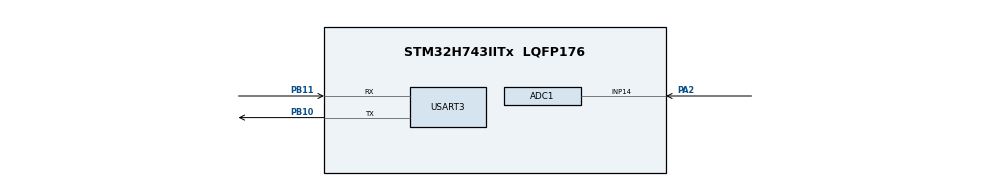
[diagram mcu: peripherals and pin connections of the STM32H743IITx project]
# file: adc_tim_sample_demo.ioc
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ADC1.Channel-0\#ChannelRegularConversion=ADC_CHANNEL_14
ADC1.ConversionDataManagement=ADC_CONVERSIONDATA_DMA_ONESHOT
ADC1.ExternalTrigConv=ADC_EXTERNALTRIG_T3_TRGO
ADC1.NbrOfConversionFlag=1
ADC1.OffsetNumber-0\#ChannelRegularConversion=ADC_OFFSET_NONE
ADC1.OffsetSignedSaturation-0\#ChannelRegularConversion=DISABLE
ADC1.Rank-0\#ChannelRegularConversion=1
ADC1.SamplingTime-0\#ChannelRegularConversion=ADC_SAMPLETIME_1CYCLE_5
ADC1.master=1
CORTEX_M7.default_mode_Activation=1
Dma.ADC1.0.Direction=DMA_PERIPH_TO_MEMORY
Dma.ADC1.0.EventEnable=DISABLE
Dma.ADC1.0.FIFOMode=DMA_FIFOMODE_DISABLE
Dma.ADC1.0.Instance=DMA1_Stream0
Dma.ADC1.0.MemDataAlignment=DMA_MDATAALIGN_HALFWORD
Dma.ADC1.0.MemInc=DMA_MINC_ENABLE
Dma.ADC1.0.Mode=DMA_NORMAL
Dma.ADC1.0.PeriphDataAlignment=DMA_PDATAALIGN_HALFWORD
Dma.ADC1.0.PeriphInc=DMA_PINC_DISABLE
Dma.ADC1.0.Polarity=HAL_DMAMUX_REQ_GEN_RISING
Dma.ADC1.0.Priority=DMA_PRIORITY_LOW
Dma.ADC1.0.RequestNumber=1
Dma.ADC1.0.SignalID=NONE
Dma.ADC1.0.SyncEnable=DISABLE
Dma.ADC1.0.SyncPolarity=HAL_DMAMUX_SYNC_NO_EVENT
Dma.ADC1.0.SyncRequestNumber=1
Dma.ADC1.0.SyncSignalID=NONE
Dma.Request0=ADC1
Mcu.Family=STM32H7
Mcu.Name=STM32H743IITx
Mcu.Package=LQFP176
NVIC.DMA1_Stream0_IRQn=true\:0\:0\:false\:false\:true\:false\:true\:true
NVIC.PriorityGroup=NVIC_PRIORITYGROUP_4
PA13\ (JTMS/SWDIO).Mode=Serial_Wire
PA13\ (JTMS/SWDIO).Signal=DEBUG_JTMS-SWDIO
PA14\ (JTCK/SWCLK).Mode=Serial_Wire
PA14\ (JTCK/SWCLK).Signal=DEBUG_JTCK-SWCLK
PA2.Signal=ADCx_INP14
PB10.Mode=Asynchronous
PB10.Signal=USART3_TX
PB11.Mode=Asynchronous
PB11.Signal=USART3_RX
PH0-OSC_IN\ (PH0).Mode=HSE-External-Clock-Source
PH0-OSC_IN\ (PH0).Signal=RCC_OSC_IN
ProjectManager.HeapSize=0x200
ProjectManager.StackSize=0x400
ProjectManager.TargetToolchain=MDK-ARM V5.32
RCC.ADCFreq_Value=75000000
RCC.APB1Freq_Value=120000000
RCC.APB2Freq_Value=120000000
RCC.APB3Freq_Value=120000000
RCC.APB4Freq_Value=120000000
RCC.CortexFreq_Value=480000000
RCC.D1PPRE=RCC_APB3_DIV2
RCC.D2PPRE1=RCC_APB1_DIV2
RCC.D2PPRE2=RCC_APB2_DIV2
RCC.D3PPRE=RCC_APB4_DIV2
RCC.DIVM1=5
RCC.DIVM2=2
RCC.DIVN1=192
RCC.DIVN2=12
RCC.HCLKFreq_Value=240000000
RCC.HPRE=RCC_HCLK_DIV2
RCC.PLL2FRACN=0
RCC.PLL3FRACN=0
RCC.PLLFRACN=0
RCC.PLLSourceVirtual=RCC_PLLSOURCE_HSE
RCC.SYSCLKFreq_VALUE=480000000
RCC.SYSCLKSource=RCC_SYSCLKSOURCE_PLLCLK
RCC.USBFreq_Value=480000000
SH.ADCx_INP14.0=ADC1_INP14,IN14-Single-Ended
TIM3.AutoReloadPreload=TIM_AUTORELOAD_PRELOAD_ENABLE
TIM3.Period=199
TIM3.Prescaler=23
TIM3.TIM_MasterOutputTrigger=TIM_TRGO_UPDATE
USART3.VirtualMode-Asynchronous=VM_ASYNC
VP_MEMORYMAP_VS_MEMORYMAP.Mode=CurAppReg
VP_TIM3_VS_ClockSourceINT.Mode=Internal
board=custom

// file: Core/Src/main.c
/* USER CODE BEGIN Header */
/**
  ******************************************************************************
  * @file           : main.c
  * @brief          : Main program body
  ******************************************************************************
  * @attention
  *
  * Copyright (c) 2026 STMicroelectronics.
  * All rights reserved.
  *
  * This software is licensed under terms that can be found in the LICENSE file
  * in the root directory of this software component.
  * If no LICENSE file comes with this software, it is provided AS-IS.
  *
  ******************************************************************************
  */
/* USER CODE END Header */
#include "main.h"
#include "adc.h"
#include "dma.h"
#include "tim.h"
#include "usart.h"
#include "gpio.h"

/* USER CODE BEGIN Includes */
#include "AdcProc.h"
#include "tjc_usart_hmi.h"
#include <stdlib.h>
#include <stdio.h>
/* USER CODE END Includes */

/* USER CODE BEGIN PD */
#define sampleLEN 2048
#define showPoints 128  // 设定发送点数，通过平均降采样实现平滑
/* USER CODE END PD */

/* USER CODE BEGIN PV */
__IO uint8_t AdcConvEnd = 0;
uint16_t ADCBuffer[sampleLEN];
/* USER CODE END PV */

void SystemClock_Config(void);
static void MPU_Config(void);
/* USER CODE BEGIN PFP */
void toShow(uint16_t* ADCBuffer, uint16_t LEN);
/* USER CODE END PFP */

int main(void)
{

  /* MPU Configuration--------------------------------------------------------*/
  MPU_Config();

  /* MCU Configuration--------------------------------------------------------*/

  /* Reset of all peripherals, Initializes the Flash interface and the Systick. */
  HAL_Init();

  /* Configure the system clock */
  SystemClock_Config();

  /* Initialize all configured peripherals */
  MX_GPIO_Init();
  MX_DMA_Init();
  MX_ADC1_Init();
  MX_TIM3_Init();
  MX_USART3_UART_Init();

  /* Infinite loop */
  while (1)
  {

    /* USER CODE BEGIN 3 */
    AdcConvEnd = 0;//刷新DMA结束标志位

	  HAL_TIM_Base_Start(&htim3);     //开启定时器3

	  //开启ADC采集，结束后触发终端回调函数HAL_ADC_ConvCpltCallback
	  HAL_ADC_Start_DMA(&hadc1, (uint32_t *)ADCBuffer, sampleLEN);

    while (!AdcConvEnd)     //等待转换完毕
		 ;

    toShow(ADCBuffer, sampleLEN); //处理ADC数据并发送

  }
  /* USER CODE END 3 */
}

void SystemClock_Config(void)
{
  RCC_OscInitTypeDef RCC_OscInitStruct = {0};
  RCC_ClkInitTypeDef RCC_ClkInitStruct = {0};

  /** Supply configuration update enable
  */
  HAL_PWREx_ConfigSupply(PWR_LDO_SUPPLY);

  /** Configure the main internal regulator output voltage
  */
  __HAL_PWR_VOLTAGESCALING_CONFIG(PWR_REGULATOR_VOLTAGE_SCALE0);

  while(!__HAL_PWR_GET_FLAG(PWR_FLAG_VOSRDY)) {}

  /** Initializes the RCC Oscillators according to the specified parameters
  * in the RCC_OscInitTypeDef structure.
  */
  RCC_OscInitStruct.OscillatorType = RCC_OSCILLATORTYPE_HSE;
  RCC_OscInitStruct.HSEState = RCC_HSE_BYPASS;
  RCC_OscInitStruct.PLL.PLLState = RCC_PLL_ON;
  RCC_OscInitStruct.PLL.PLLSource = RCC_PLLSOURCE_HSE;
  RCC_OscInitStruct.PLL.PLLM = 5;
  RCC_OscInitStruct.PLL.PLLN = 192;
  RCC_OscInitStruct.PLL.PLLP = 2;
  RCC_OscInitStruct.PLL.PLLQ = 2;
  RCC_OscInitStruct.PLL.PLLR = 2;
  RCC_OscInitStruct.PLL.PLLRGE = RCC_PLL1VCIRANGE_2;
  RCC_OscInitStruct.PLL.PLLVCOSEL = RCC_PLL1VCOWIDE;
  RCC_OscInitStruct.PLL.PLLFRACN = 0;
  if (HAL_RCC_OscConfig(&RCC_OscInitStruct) != HAL_OK)
  {
    Error_Handler();
  }

  /** Initializes the CPU, AHB and APB buses clocks
  */
  RCC_ClkInitStruct.ClockType = RCC_CLOCKTYPE_HCLK|RCC_CLOCKTYPE_SYSCLK
                              |RCC_CLOCKTYPE_PCLK1|RCC_CLOCKTYPE_PCLK2
                              |RCC_CLOCKTYPE_D3PCLK1|RCC_CLOCKTYPE_D1PCLK1;
  RCC_ClkInitStruct.SYSCLKSource = RCC_SYSCLKSOURCE_PLLCLK;
  RCC_ClkInitStruct.SYSCLKDivider = RCC_SYSCLK_DIV1;
  RCC_ClkInitStruct.AHBCLKDivider = RCC_HCLK_DIV2;
  RCC_ClkInitStruct.APB3CLKDivider = RCC_APB3_DIV2;
  RCC_ClkInitStruct.APB1CLKDivider = RCC_APB1_DIV2;
  RCC_ClkInitStruct.APB2CLKDivider = RCC_APB2_DIV2;
  RCC_ClkInitStruct.APB4CLKDivider = RCC_APB4_DIV2;

  if (HAL_RCC_ClockConfig(&RCC_ClkInitStruct, FLASH_LATENCY_4) != HAL_OK)
  {
    Error_Handler();
  }
}

/* USER CODE BEGIN 4 */
void HAL_ADC_ConvCpltCallback(ADC_HandleTypeDef *hadc)
{
    if (hadc->Instance == ADC1) //检查触发中断的ADC身份
    {
        AdcConvEnd = 1; //设置DMA结束标志位
        HAL_TIM_Base_Stop(&htim3); //关闭定时器
    }
}

/**
 * @brief 处理 ADC 缓冲区，提取一个周期，缩放至 0-200 并重采样为固定点数发送
 */
void toShow(uint16_t* ADCBuffer, uint16_t LEN) {
    uint16_t cycleLen = 0;

    // 1. 提取一个周期的采样点
    // 注意：此函数内部 malloc 分配内存，必须手动 free
    uint16_t* oneCycleData = find_one_cycle(ADCBuffer, LEN, &cycleLen);

    if (oneCycleData == NULL) {
        //printf("未找到完整周期\n");
        return;
    }

    // 2. 将电压值等比例缩放到 0 - 200 范围
    // 这样做可以确保无论原始采样精度如何，最终输出都在 0-200 之间
    scale_array(oneCycleData, cycleLen, 0, 200);

    // 3. 自适应重采样：无论原始周期有多少点，统一变换为 200 点输出
    // 480个点实现五个周期，平均每个周期96点，重采样为90点可以平滑显示
    uint16_t targetPoints = 90; // 设定发送点数，通过平均降采样实现平滑
    uint16_t sendBuffer[targetPoints];

    resample_u16(oneCycleData, cycleLen, sendBuffer, targetPoints);

    // 4. 发送数据
    for (int i = 0; i < targetPoints; i++) {
        TJCPrintf("add s0.id,0,%d", sendBuffer[i]);
			  HAL_Delay(10);
    }

    // 5. 必须释放 find_one_cycle 申请的堆空间
    free(oneCycleData);
}

/* USER CODE END 4 */

 /* MPU Configuration */

void MPU_Config(void)
{
  MPU_Region_InitTypeDef MPU_InitStruct = {0};

  /* Disables the MPU */
  HAL_MPU_Disable();

  /** Initializes and configures the Region and the memory to be protected
  */
  MPU_InitStruct.Enable = MPU_REGION_ENABLE;
  MPU_InitStruct.Number = MPU_REGION_NUMBER0;
  MPU_InitStruct.BaseAddress = 0x0;
  MPU_InitStruct.Size = MPU_REGION_SIZE_4GB;
  MPU_InitStruct.SubRegionDisable = 0x87;
  MPU_InitStruct.TypeExtField = MPU_TEX_LEVEL0;
  MPU_InitStruct.AccessPermission = MPU_REGION_NO_ACCESS;
  MPU_InitStruct.DisableExec = MPU_INSTRUCTION_ACCESS_DISABLE;
  MPU_InitStruct.IsShareable = MPU_ACCESS_SHAREABLE;
  MPU_InitStruct.IsCacheable = MPU_ACCESS_NOT_CACHEABLE;
  MPU_InitStruct.IsBufferable = MPU_ACCESS_NOT_BUFFERABLE;

  HAL_MPU_ConfigRegion(&MPU_InitStruct);
  /* Enables the MPU */
  HAL_MPU_Enable(MPU_PRIVILEGED_DEFAULT);

}

void Error_Handler(void)
{
  __disable_irq();
  while (1)
  {
  }
}
